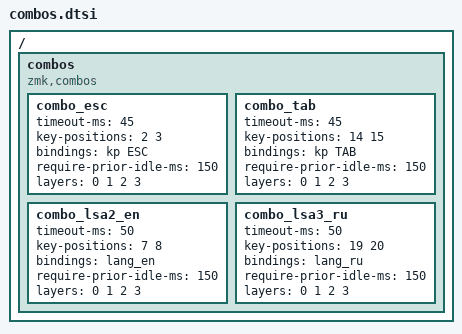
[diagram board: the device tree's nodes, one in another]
/*
 * Комбо-сочетания для Charybdis Mini MOD (42 клавиши: 3x6 + 3L/3R Thumbs)
 *
 * Точные комбо:
 *   W + E (02 + 03) -> Esc (с защитой от роллов require-prior-idle-ms = 150)
 *   S + D (14 + 15) -> Tab (с защитой от роллов require-prior-idle-ms = 150)
 *   U + I (07 + 08) -> lang_en (Alt+Shift+2 в Windows)
 *   J + K (19 + 20) -> lang_ru (Alt+Shift+3 в Windows)
 */

/ {
    combos {
        compatible = "zmk,combos";

        /* W + E (2 + 3) -> Esc */
        combo_esc {
            timeout-ms = <45>;
            key-positions = <2 3>;
            bindings = <&kp ESC>;
            require-prior-idle-ms = <150>;
            layers = <0 1 2 3>;
        };

        /* S + D (14 + 15) -> Tab */
        combo_tab {
            timeout-ms = <45>;
            key-positions = <14 15>;
            bindings = <&kp TAB>;
            require-prior-idle-ms = <150>;
            layers = <0 1 2 3>;
        };

        /* U + I (7 + 8) -> Alt+Shift+2 (Английский EN в Windows) */
        combo_lsa2_en {
            timeout-ms = <50>;
            key-positions = <7 8>;
            bindings = <&lang_en>;
            require-prior-idle-ms = <150>;
            layers = <0 1 2 3>;
        };

        /* J + K (19 + 20) -> Alt+Shift+3 (Русский RU в Windows) */
        combo_lsa3_ru {
            timeout-ms = <50>;
            key-positions = <19 20>;
            bindings = <&lang_ru>;
            require-prior-idle-ms = <150>;
            layers = <0 1 2 3>;
        };
    };
};
